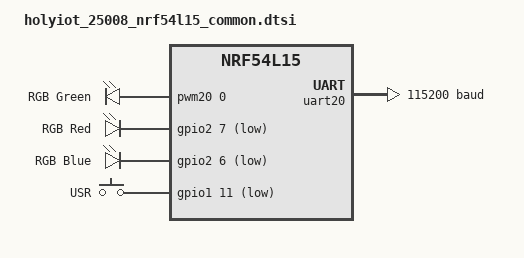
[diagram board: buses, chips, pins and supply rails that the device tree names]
/*
 * Copyright (c) 2025
 * SPDX-License-Identifier: Apache-2.0
 */

#include "holyiot_25008_nrf54l15-pinctrl.dtsi"
#include <zephyr/dt-bindings/input/input-event-codes.h>

/ {
	/* Green is on P1.09 — reachable by LP-domain PWM20. */
	rgb_led: pwmleds {
		compatible = "pwm-leds";
		led_g: led_g {
			pwms = <&pwm20 0 PWM_MSEC(20) PWM_POLARITY_INVERTED>;
			label = "RGB Green";
		};
	};

	/* Red (P2.07) and Blue (P2.06) are on the MCU-domain P2 port which
	 * LP-domain PWM cannot reach, so they are driven as GPIO on/off. */
	gpio_rgb: leds {
		compatible = "gpio-leds";
		led_r: led_r {
			gpios = <&gpio2 7 GPIO_ACTIVE_LOW>;
			label = "RGB Red";
		};
		led_b: led_b {
			gpios = <&gpio2 6 GPIO_ACTIVE_LOW>;
			label = "RGB Blue";
		};
	};

	buttons: buttons {
		compatible = "gpio-keys";

		usr_btn: usr-btn {
			gpios = <&gpio1 11 (GPIO_PULL_UP | GPIO_ACTIVE_LOW)>;
			label = "USR";
			zephyr,code = <INPUT_KEY_ENTER>;
		};
	};

	aliases {
		led-red = &led_r;
		led-green = &led_g;
		led-blue = &led_b;
		sw0 = &usr_btn;
		buttons = &buttons;
		watchdog0 = &wdt31;
	};
};

&uart20 {
	current-speed = <115200>;
	pinctrl-0 = <&uart20_default>;
	pinctrl-1 = <&uart20_sleep>;
	pinctrl-names = "default", "sleep";
};

&spi00 {
	pinctrl-0 = <&spi00_default>;
	pinctrl-1 = <&spi00_sleep>;
	pinctrl-names = "default", "sleep";
};

&pwm20 {
	pinctrl-0 = <&pwm20_default>;
	pinctrl-1 = <&pwm20_sleep>;
	pinctrl-names = "default", "sleep";
};
